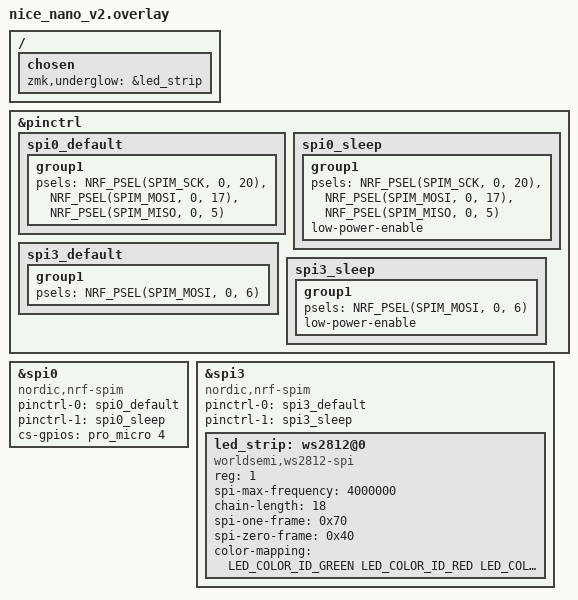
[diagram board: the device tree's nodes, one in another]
#include <dt-bindings/led/led.h>

&pinctrl {
    //
    // nice!View config
    //
    spi0_default: spi0_default {
        group1 {
            psels = <NRF_PSEL(SPIM_SCK, 0, 20)>,  // Pin 6 SCK, D3
                    <NRF_PSEL(SPIM_MOSI, 0, 17)>, // Pin 5 MOSI, D2
                    <NRF_PSEL(SPIM_MISO, 0, 5)>;  // no idea, this pin doesn't exist?
        };
    };

    spi0_sleep: spi0_sleep {
        group1 {
            psels = <NRF_PSEL(SPIM_SCK, 0, 20)>,  // Pin 6 SCK, D3
                    <NRF_PSEL(SPIM_MOSI, 0, 17)>, // Pin 5 MOSI, D2
                    <NRF_PSEL(SPIM_MISO, 0, 5)>;  // See above note
            low-power-enable;
        };
    };

    //
    // LED Underglow config
    //
    spi3_default: spi3_default {
        group1 {
            psels = <NRF_PSEL(SPIM_MOSI, 0, 6)>;
        };
    };

    spi3_sleep: spi3_sleep {
        group1 {
            psels = <NRF_PSEL(SPIM_MOSI, 0, 6)>;
            low-power-enable;
        };
    };
};

nice_view_spi: &spi0 {
    status = "okay";
    compatible = "nordic,nrf-spim";
    pinctrl-0 = <&spi0_default>;
    pinctrl-1 = <&spi0_sleep>;
    pinctrl-names = "default", "sleep";
    cs-gpios = <&pro_micro 4 GPIO_ACTIVE_HIGH>;
};

ws2812_spi: &spi3 {
    compatible = "nordic,nrf-spim";
    status = "okay";
    pinctrl-0 = <&spi3_default>;
    pinctrl-1 = <&spi3_sleep>;
    pinctrl-names = "default", "sleep";

    led_strip: ws2812@0 {
        compatible = "worldsemi,ws2812-spi";

        /* SPI */
        reg = <1>; /* ignored, but necessary for SPI bindings */
        spi-max-frequency = <4000000>;

        /* WS2812 */
        chain-length = <18>; /* arbitrary; change at will */
        spi-one-frame = <0x70>;
        spi-zero-frame = <0x40>;

        color-mapping = <LED_COLOR_ID_GREEN LED_COLOR_ID_RED LED_COLOR_ID_BLUE>;
    };
};

/ {
    chosen {
        zmk,underglow = &led_strip;
    };
};
